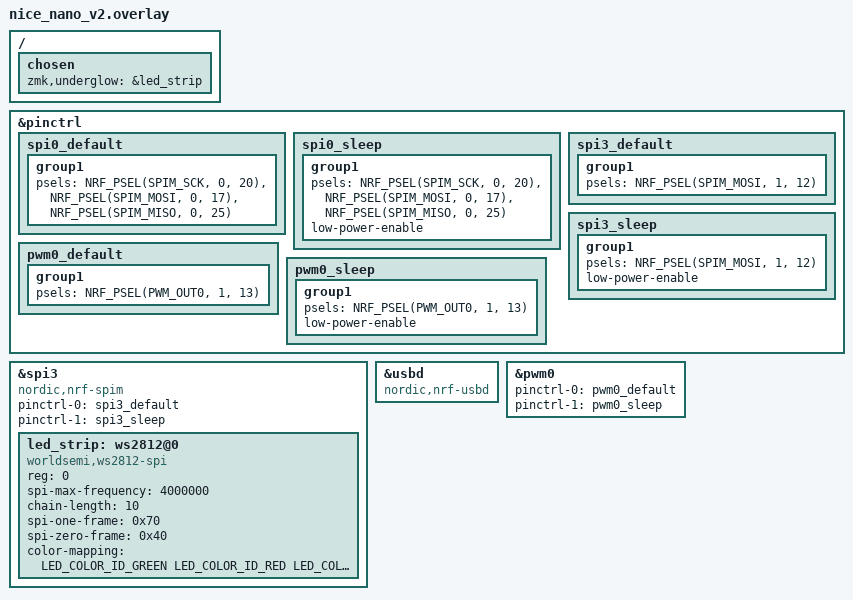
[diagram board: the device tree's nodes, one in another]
#include <dt-bindings/led/led.h>

&pinctrl {

    spi0_default: spi0_default {
        group1 {
            psels = <NRF_PSEL(SPIM_SCK, 0, 20)>,
                <NRF_PSEL(SPIM_MOSI, 0, 17)>,
                <NRF_PSEL(SPIM_MISO, 0, 25)>;
        };
    };

    spi0_sleep: spi0_sleep {
        group1 {
            psels = <NRF_PSEL(SPIM_SCK, 0, 20)>,
                <NRF_PSEL(SPIM_MOSI, 0, 17)>,
                <NRF_PSEL(SPIM_MISO, 0, 25)>;
            low-power-enable;
        };
    };

    spi3_default: spi3_default {
        group1 {
            psels = <NRF_PSEL(SPIM_MOSI, 1, 12)>; // WS2812_VEXT_DATA
        };
    };

    spi3_sleep: spi3_sleep {
        group1 {
            psels = <NRF_PSEL(SPIM_MOSI, 1, 12)>;
            low-power-enable;
        };
    };
    pwm0_default: pwm0_default {
        group1 {
            psels = <NRF_PSEL(PWM_OUT0, 1, 13)>;
        };
    };
    pwm0_sleep: pwm0_sleep {
        group1 {
            psels = <NRF_PSEL(PWM_OUT0, 1, 13)>;
            low-power-enable;
        };
    };
};

&spi3 {
    compatible = "nordic,nrf-spim";
    status = "okay";

    pinctrl-0 = <&spi3_default>;
    pinctrl-1 = <&spi3_sleep>;
    pinctrl-names = "default", "sleep";

    led_strip: ws2812@0 {
        compatible = "worldsemi,ws2812-spi";

        /* SPI */
        reg = <0>; /* ignored, but necessary for SPI bindings */
        spi-max-frequency = <4000000>;

        /* WS2812 */
        chain-length = <10>; /* arbitrary; change at will */
        spi-one-frame = <0x70>;
        spi-zero-frame = <0x40>;

        color-mapping = <LED_COLOR_ID_GREEN LED_COLOR_ID_RED LED_COLOR_ID_BLUE>;
    };
};

/ {
    chosen {
        zmk,underglow = &led_strip;
    };
};
// vim: filetype=dts fdm=marker:
zephyr_udc0: &usbd {
    compatible = "nordic,nrf-usbd";
    status = "okay";
};

&pwm0 {
    status = "okay";
    pinctrl-0 = <&pwm0_default>;
    pinctrl-1 = <&pwm0_sleep>;
    pinctrl-names = "default", "sleep";
};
